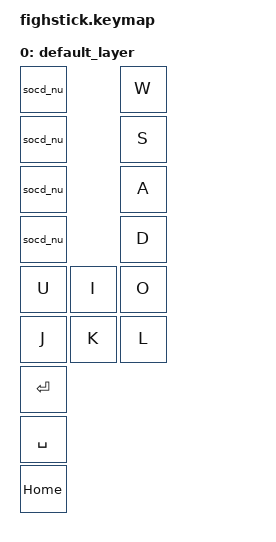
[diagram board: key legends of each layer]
#include <behaviors.dtsi>
#include <dt-bindings/zmk/keys.h>
#include <dt-bindings/zmk/bt.h>

/ {
    // Define a custom SOCD behavior. NU = Neutral.
    // This means L+R = Neutral, and U+D = Neutral.
    behaviors {
        socd_nu: socd_nu {
            compatible = "zmk,behavior-socd";
            #binding-cells = <1>;
            bindings = <&kp>, <&kp>;
            mode = "nu"; // Neutral mode
        };
    };

    keymap {
        compatible = "zmk,keymap";

        default_layer {
            // This order MUST match the order of pins in your fightstick.overlay file.
            // The correct syntax is &behavior <parameter>. Here, the parameter is a key press.
            bindings = <
                // Joystick (Up, Down, Left, Right)
                &socd_nu <&kp W>      // Correct: Apply SOCD logic to the key press 'W'
                &socd_nu <&kp S>      // Correct: Apply SOCD logic to the key press 'S'
                &socd_nu <&kp A>      // Correct: Apply SOCD logic to the key press 'A'
                &socd_nu <&kp D>      // Correct: Apply SOCD logic to the key press 'D'
                
                // 6 Action Buttons (B1-B6)
                &kp U &kp I &kp O
                &kp J &kp K &kp L
                
                // 3 Function Buttons (Start, Select, Home)
                &kp ENTER
                &kp SPACE
                &kp HOME
            >;
        };
    };
};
